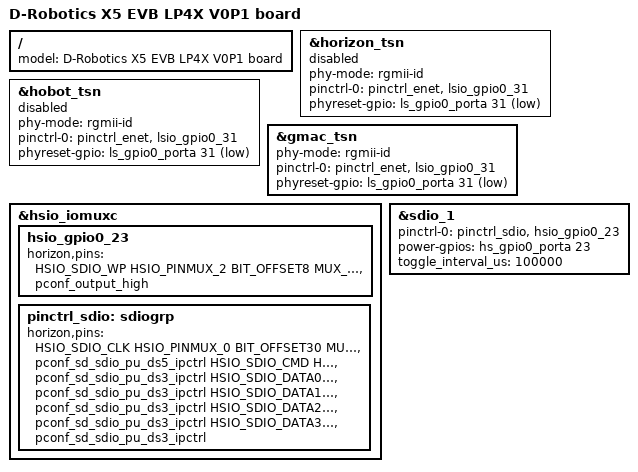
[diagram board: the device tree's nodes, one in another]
// SPDX-License-Identifier: GPL-2.0
/*
 * dts for Sunrise5 EVB LP4X V0P1 board
 *
 * Copyright (C) 2024 D-Robotics Inc.
 *
 */

/dts-v1/;
#include "x5-evb.dtsi"

/ {
	model = "D-Robotics X5 EVB LP4X V0P1 board";
};

&horizon_tsn {
	status = "disabled";

	phy-mode = "rgmii-id";
	pinctrl-names = "default";
	pinctrl-0 = <&pinctrl_enet &lsio_gpio0_31>;
	phyreset-gpio = <&ls_gpio0_porta 31 GPIO_ACTIVE_LOW>;
};

&hobot_tsn {
	status = "disabled";

	phy-mode = "rgmii-id";
	pinctrl-names = "default";
	pinctrl-0 = <&pinctrl_enet &lsio_gpio0_31>;
	phyreset-gpio = <&ls_gpio0_porta 31 GPIO_ACTIVE_LOW>;
};

&gmac_tsn {
	/* Use gmac_tsn or hobot_tsn for evb v1p2 board currently,
	   horizon_tsn driver is not ready yet... */
	status = "okay";

	phy-mode = "rgmii-id";
	pinctrl-names = "default";
	pinctrl-0 = <&pinctrl_enet &lsio_gpio0_31>;
	phyreset-gpio = <&ls_gpio0_porta 31 GPIO_ACTIVE_LOW>;
};

/* ANT_CTRL1 */
&hsio_iomuxc {
	hsio_gpio0_23: hsio_gpio0_23 {
		horizon,pins = <
			HSIO_SDIO_WP	HSIO_PINMUX_2	BIT_OFFSET8		MUX_ALT2	&pconf_output_high
		>;
	};

	pinctrl_sdio: sdiogrp {
		horizon,pins = <
			HSIO_SDIO_CLK	HSIO_PINMUX_0	BIT_OFFSET30	MUX_ALT0	&pconf_sd_sdio_pu_ds5_ipctrl
			HSIO_SDIO_CMD	HSIO_PINMUX_0	BIT_OFFSET28	MUX_ALT0	&pconf_sd_sdio_pu_ds3_ipctrl
			HSIO_SDIO_DATA0	HSIO_PINMUX_1	BIT_OFFSET0		MUX_ALT0	&pconf_sd_sdio_pu_ds3_ipctrl
			HSIO_SDIO_DATA1	HSIO_PINMUX_2	BIT_OFFSET30	MUX_ALT0	&pconf_sd_sdio_pu_ds3_ipctrl
			HSIO_SDIO_DATA2	HSIO_PINMUX_2	BIT_OFFSET28	MUX_ALT0	&pconf_sd_sdio_pu_ds3_ipctrl
			HSIO_SDIO_DATA3	HSIO_PINMUX_2	BIT_OFFSET26	MUX_ALT0	&pconf_sd_sdio_pu_ds3_ipctrl
		>;
	};
};

/* SDIO */
&sdio_1 {
	status = "okay";

	pinctrl-names = "default";
	pinctrl-0 = <&pinctrl_sdio &hsio_gpio0_23>;
	power-gpios = <&hs_gpio0_porta 23 GPIO_ACTIVE_HIGH>;
	toggle_interval_us = <100000>;
};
